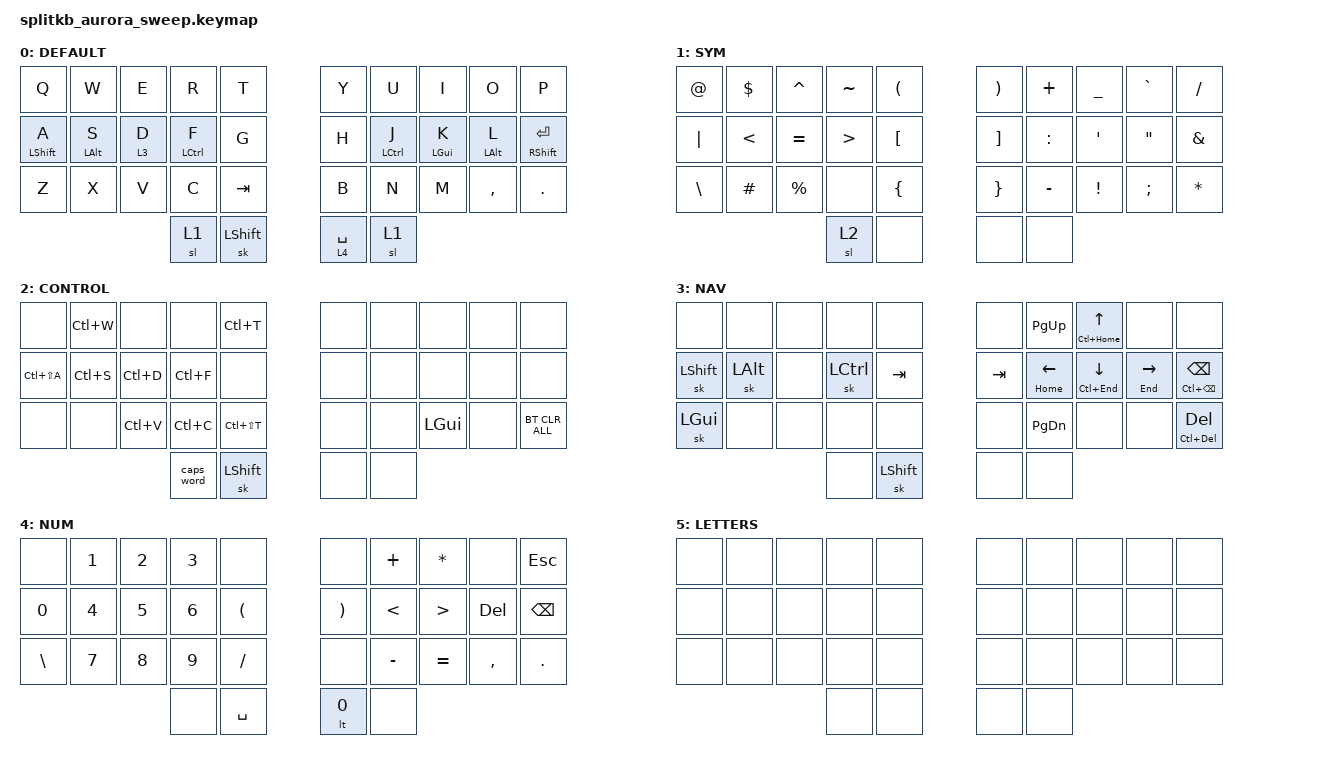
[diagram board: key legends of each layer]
/* 
 * Copyright (c) 2022 The ZMK Contributors
 *
 * SPDX-License-Identifier: MIT
 */

#include <behaviors.dtsi>
#include <dt-bindings/zmk/keys.h>
#include <dt-bindings/zmk/bt.h>

#define ___       &none

&sk {  // sticky-key config
    release-after-ms = <900>;  // release after 0.6s
    quick-release;             // no double capitalization when rolling keys
};

&sl {  // sticky-layer config
    ignore-modifiers;          // allow chording sticky mods & layers
};

&lt {  // layer-tap config
    flavor = "balanced";
    tapping-term-ms = <200>;
    quick-tap-ms = <150>;
};

&mt {
    flavor = "tap-preferred";
    tapping-term-ms = <220>; 
    quick-tap-ms = <220>; 
};

/ {
    behaviors {
    smart_shft: smart_shft {
            compatible = "zmk,behavior-mod-morph";
            #binding-cells = <0>;
            bindings = <&sk LSHFT>, <&caps_word>;
            mods = <(MOD_LSFT|MOD_RSFT)>;
       };
    
};

#define DEFAULT 0
#define SYM 1
#define CONTROL 2
#define NAV 3

#define NUM 4 
#define LETTERS 5

#define NAV_LEFT  &mt HOME LEFT    // tap: left  | long-tap: beginning of line
#define NAV_RIGHT &mt END RIGHT   // tap: right | long-tap: end       of line
#define NAV_UP    &mt LC(HOME) UP      // tap: up    | long-tap: beginning of document
#define NAV_DOWN  &mt LC(END)  DOWN    // tap: down  | long-tap: end       of document
#define NAV_BSPC  &mt LC(BSPC) BSPC    // tap: bspc  | long-tap: delete word backward
#define NAV_DEL   &mt LC(DEL)  DEL     // tap: del   | long-tap: delete word forward

keymap {
                compatible = "zmk,keymap";

        DEFAULT { bindings = <  
        //╭─────────────┬─────────────┬─────────────┬─────────────┬─────────────╮ ╭─────────────┬─────────────┬─────────────┬─────────────┬─────────────╮
            &kp Q         &kp W         &kp E         &kp R         &kp T           &kp Y         &kp U         &kp I         &kp O         &kp P
        //├─────────────┼─────────────┼─────────────┼─────────────┼─────────────┤ ├─────────────┼─────────────┼─────────────┼─────────────┼─────────────┤
            &mt LSHFT A   &mt LALT S    &lt 3 D       &mt LCTRL F   &kp G           &kp H         &mt LCTRL J   &mt LGUI K    &mt LALT L    &mt RSHFT ENTER
        //├─────────────┼─────────────┼─────────────┼─────────────┼─────────────┤ ├─────────────┼─────────────┼─────────────┼─────────────┼─────────────┤
            &kp Z         &kp X         &kp V         &kp C         &kp TAB         &kp B         &kp N         &kp M         &kp COMMA     &kp DOT
        //╰─────────────┼─────────────┴─────────────┼─────────────┼─────────────┤ ├─────────────┼─────────────┼─────────────┴───────────────────────────╯ 
                                                      &sl 1         &sk LSHFT       &lt 4 SPACE   &sl 1                         
        //                                          ╰─────────────┴─────────────╯ ╰─────────────┴─────────────╯                                           
>;};
        SYM { bindings = <  
        //╭─────────────┬─────────────┬─────────────┬─────────────┬─────────────╮ ╭─────────────┬─────────────┬─────────────┬─────────────┬─────────────╮
            &kp AT        &kp DOLLAR    &kp CARET     &kp TILDE     &kp LPAR        &kp RPAR       &kp PLUS    &kp UNDER      &kp GRAVE     &kp FSLH         
        //├─────────────┼─────────────┼─────────────┼─────────────┼─────────────┤ ├─────────────┼─────────────┼─────────────┼─────────────┼─────────────┤
            &kp PIPE      &kp LT        &kp EQUAL     &kp GT        &kp LBKT        &kp RBKT       &kp COLON   &kp SQT        &kp DQT       &kp AMPERSAND
        //├─────────────┼─────────────┼─────────────┼─────────────┼─────────────┤ ├─────────────┼─────────────┼─────────────┼─────────────┼─────────────┤
            &kp BSLH      &kp POUND     &kp PERCENT   ___           &kp LBRC        &kp RBRC       &kp MINUS   &kp EXCL       &kp SEMI      &kp STAR
        //╰─────────────┼─────────────┴─────────────┼─────────────┼─────────────┤ ├─────────────┼─────────────┼─────────────┴───────────────────────────╯ 
                                                      &sl 2         ___             ___           ___
        //                                          ╰─────────────┴─────────────╯ ╰─────────────┴─────────────╯                                           
>;};

        CONTROL { bindings = <  
        //╭─────────────┬─────────────┬─────────────┬─────────────┬─────────────╮ ╭─────────────┬─────────────┬─────────────┬─────────────┬─────────────╮
            ___           &kp LC(W)     ___           ___           &kp LC(T)       ___           ___           ___           ___           ___                    
        //├─────────────┼─────────────┼─────────────┼─────────────┼─────────────┤ ├─────────────┼─────────────┼─────────────┼─────────────┼─────────────┤
            &kp LC(LS(A)) &kp LC(S)     &kp LC(D)     &kp LC(F)     ___             ___           ___           ___           ___           ___           
        //├─────────────┼─────────────┼─────────────┼─────────────┼─────────────┤ ├─────────────┼─────────────┼─────────────┼─────────────┼─────────────┤
            ___           ___           &kp LC(V)     &kp LC(C)     &kp LC(LS(T))   &none         ___           &kp LGUI      ___           &bt BT_CLR_ALL
        //╰─────────────┼─────────────┴─────────────┼─────────────┼─────────────┤ ├─────────────┼─────────────┼─────────────┴───────────────────────────╯ 
                                                      &caps_word    &sk LSHFT       &none         &none         
        //                                          ╰─────────────┴─────────────╯ ╰─────────────┴─────────────╯                                           
>;};

    NAV { bindings = <  
        //╭─────────────┬─────────────┬─────────────┬─────────────┬─────────────╮ ╭─────────────┬─────────────┬─────────────┬─────────────┬─────────────╮
            ___           ___           ___           ___           ___             ___           &kp PG_UP     NAV_UP        ___           ___                                
        //├─────────────┼─────────────┼─────────────┼─────────────┼─────────────┤ ├─────────────┼─────────────┼─────────────┼─────────────┼─────────────┤
            &sk LSHFT     &sk LALT      ___           &sk LCTRL     &kp TAB         &kp TAB       NAV_LEFT      NAV_DOWN      NAV_RIGHT     NAV_BSPC
        //├─────────────┼─────────────┼─────────────┼─────────────┼─────────────┤ ├─────────────┼─────────────┼─────────────┼─────────────┼─────────────┤
            &sk LGUI      ___           ___           ___           ___             ___           &kp PG_DN     ___           ___           NAV_DEL
        //╰─────────────┼─────────────┴─────────────┼─────────────┼─────────────┤ ├─────────────┼─────────────┼─────────────┴───────────────────────────╯ 
                                                      ___           &sk LSHFT       &none         &none                
        //                                          ╰─────────────┴─────────────╯ ╰─────────────┴─────────────╯                                           
>;};    

    NUM { bindings = <  
        //╭─────────────┬─────────────┬─────────────┬─────────────┬─────────────╮ ╭─────────────┬─────────────┬─────────────┬─────────────┬─────────────╮
            ___           &kp N1        &kp N2        &kp N3        ___             ___           &kp PLUS      &kp STAR      ___           &kp ESC
        //├─────────────┼─────────────┼─────────────┼─────────────┼─────────────┤ ├─────────────┼─────────────┼─────────────┼─────────────┼─────────────┤
            &kp N0        &kp N4        &kp N5        &kp N6        &kp LPAR        &kp RPAR      &kp LT        &kp GT        &kp DEL       &kp BSPC
        //├─────────────┼─────────────┼─────────────┼─────────────┼─────────────┤ ├─────────────┼─────────────┼─────────────┼─────────────┼─────────────┤
            &kp BSLH      &kp N7        &kp N8        &kp N9        &kp FSLH        ___           &kp MINUS     &kp EQUAL     &kp COMMA     &kp DOT
        //╰─────────────┼─────────────┴─────────────┼─────────────┼─────────────┤ ├─────────────┼─────────────┼─────────────┴───────────────────────────╯ 
                                                      ___           &kp SPACE       &lt 0         &none     
        //                                          ╰─────────────┴─────────────╯ ╰─────────────┴─────────────╯                                           
>;};
    LETTERS { bindings = <  
        //╭─────────────┬─────────────┬─────────────┬─────────────┬─────────────╮ ╭─────────────┬─────────────┬─────────────┬─────────────┬─────────────╮
            ___           ___           ___           ___           ___             ___           ___           ___           ___           ___         
        //├─────────────┼─────────────┼─────────────┼─────────────┼─────────────┤ ├─────────────┼─────────────┼─────────────┼─────────────┼─────────────┤
            ___           ___           ___           ___           ___             ___           ___           ___           ___           ___
        //├─────────────┼─────────────┼─────────────┼─────────────┼─────────────┤ ├─────────────┼─────────────┼─────────────┼─────────────┼─────────────┤
            ___           ___           ___           ___           ___             ___           ___           ___           ___           ___
        //╰─────────────┼─────────────┴─────────────┼─────────────┼─────────────┤ ├─────────────┼─────────────┼─────────────┴───────────────────────────╯ 
                                                      ___           ___             ___           ___                                       
        //                                          ╰─────────────┴─────────────╯ ╰─────────────┴─────────────╯                                           
>;};
    };
};
